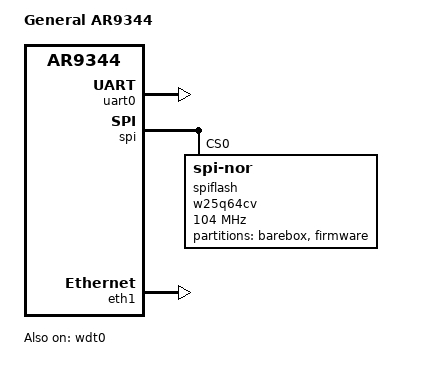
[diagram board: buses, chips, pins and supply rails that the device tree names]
/dts-v1/;

#include <dt-bindings/gpio/gpio.h>
#include <dt-bindings/input/input.h>

#include "ar9344.dtsi"

/ {
	model = "General AR9344";
	compatible = "general,ar9344";

	aliases {
		serial0 = &uart0;
		spiflash = &spiflash;
		spi0 = &spi;
	};

	chosen {
		stdout-path = &uart0;
	};
};

&gpio {
	status = "okay";
};

&uart0 {
	status = "okay";
};

&wdt0 {
	status = "okay";
};

&spi {
	num-chipselects = <1>;
	status = "okay";

	/* Winbond W25Q64CV SPI flash */
	spiflash: w25q64cv@0 {
		#address-cells = <1>;
		#size-cells = <1>;
		compatible = "jedec,spi-nor", "winbond,w25q64cv";
		spi-max-frequency = <104000000>;
		reg = <0>;

        partition@0 {
            label = "barebox";
            reg = <0 0x20000>;  /* 128K */
        };

        partition@20000 {
            label = "firmware";
            reg = <0x20000 0x7d0000>;
        };
	};
};

&eth1 {
	status = "okay";
};
